# H6 register map
Vendor: Allwinner; Series: H6; File version: 0.1
CPU: CA53 0, little endian, MPU, no FPU, 0 interrupt priority bits
Registers are 32-bit, read-write, reset 0x0 unless marked. A register's access mark holds for its fields unless they carry their own. Offsets are from the block's base; lines under a group give offsets from that group; [hi:lo] are bit positions; {n}, {i} and the like mark numbered series; 'fields as' and 'values as' point back to an identical list; <NAME> marks a mode.

## Memory map
0x00004000 ATE_TV_Encoder
0x00006000 ATE_EPHY
0x01904000 CE_NS
0x01904800 CE_S
0x01905000 EMCE
0x03000000 SYS_CFG
0x03001000 CCU
0x03002000 DMA
0x03003000 MSGBOX
0x03004000 Spinlock
0x03005000 High_Speed_Timer
0x03009000 Timer
0x0300A000 PWM
0x0300B000 PIO
0x030F0000 IOMMU
0x04011000 NDFC0
0x04020000 SMHC0
0x04021000 SMHC1
0x04022000 SMHC2
0x05000000 UART0
0x05000400 UART1
0x05000800 UART2
0x05000C00 UART3
0x05002000 TWI0
0x05002400 TWI1
0x05002800 TWI2
0x05005000 SCR0
0x05005400 SCR1
0x05010000 SPI0
0x05011000 SPI1
0x05020000 EMAC
0x05060000 TSC
0x05060040 TSG
0x05060100 TSF0
0x05060180 TSD0
0x05060200 TSF1
0x05060280 TSD1
0x05060300 TSF2
0x05060380 TSD2
0x05060400 TSF3
0x05060480 TSD3
0x05060500 TSF4
0x05060580 TSD4
0x05070400 CIR_TX
0x05070400 Thermal_Sensor
0x0508F000 I2S/PCM3(used_for_Audio_Codec)
0x05090000 I2S/PCM0
0x05091000 I2S/PCM1(used_for_HDMI)
0x05092000 I2S/PCM2
0x05093000 OWA
0x05095000 DMIC
0x05097000 AHUB
0x05311000 USB2.0_HOST
0x06511000 TCON_LCD0
0x06515000 TCON_TV0
0x06620000 CSI_BASE
0x06620000 CSI_TOP
0x06621000 CSI_PARSER
0x06623000 CSI_DMA0
0x06623100 CSI_DMA1
0x0662E000 CSI_CCI0
0x07000000 RTC
0x07022000 PIO
0x07040000 CIR_RX
0x07040400 R_OWC
0x07080000 R_UART0
0x07081400 R-TWI
0x08100000 CPU_SUBSYS_CTRL
0x09010000 CPU_CFG

## SYS_CFG
Base 0x03000000
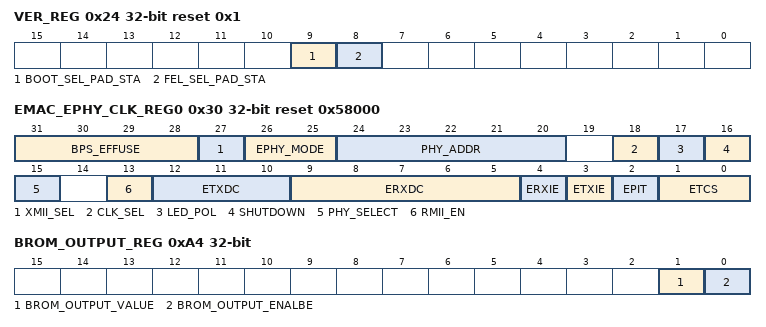
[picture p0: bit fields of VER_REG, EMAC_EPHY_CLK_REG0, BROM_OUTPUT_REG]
0x24 VER_REG reset 0x1 (reset mask 0xFFFF8007) — Version Register
  [9] BOOT_SEL_PAD_STA ro — 0:SMHC0->SMHC2->NAND FLASH->SPI_NOR 1:SMHC0->NAND FLASH->SMHC2->SPI_NOR
  [8] FEL_SEL_PAD_STA ro — Fel_Select_Pin_Status 0: Run_FEL 1:Try Media Boot
    0=Run_FEL; 1=Try (Try Media Boot)
0x30 EMAC_EPHY_CLK_REG0 reset 0x58000 — EMAC-EPHY Clock Register 0
  [31:28] BPS_EFFUSE
  [27] XMII_SEL — 0: Internal SMI and MII 1: External SMI and MII
    0=Internal SMI and MII; 1=External SMI and MII
  [26:25] EPHY_MODE — Operation Mode Selection 00 : Normal Mode 01 : Sim Mode 10 : AFE Test Mode 11 : /
  [24:20] PHY_ADDR — PHY Address
  [18] CLK_SEL — 0 : 25MHz 1 : 24MHz
  [17] LED_POL — 0 : High active 1 : Low active
  [16] SHUTDOWN — 0 : Power up 1 : Shutdown
  [15] PHY_SELECT — 0 : External PHY 1 : Internal PHY
  [13] RMII_EN — 0 : Disable RMII Module 1 : Enable RMII Module When this bit assert, MII or RGMII interface is disabled( This means bit13 is prior to bit2)
  [12:10] ETXDC — Configure EMAC Transmit Clock Delay Chain.
  [9:5] ERXDC — Configure EMAC Receive Clock Delay Chain.
  [4] ERXIE — Enable EMAC Receive Clock Invertor. 0: Disable 1: Enable
    0=Disable; 1=Enable
  [3] ETXIE — Enable EMAC Transmit Clock Invertor. 0: Disable 1: Enable
    0=Disable; 1=Enable
  [2] EPIT — EMAC PHY Interface Type 0: MII 1: RGMII
    0=MII; 1=RGMII
  [1:0] ETCS — EMAC Transmit Clock Source 00: Transmit clock source for MII 01: External transmit clock source for RMII and RGMII 10: Internal transmit clock source for RMII and RGMII 11: Reserved
    0=Transmit clock source for MII; 1=External transmit clock source for RMII and RGMII; 2=Internal transmit clock source for RMII and RGMII
0xA4 BROM_OUTPUT_REG — BROM Output Register
  [1] BROM_OUTPUT_VALUE — 0: U-Boot pin output 0 1: U-Boot pin output 1
    0=U_minus_Boot_pin_output_0 (U-Boot pin output 0); 1=U_minus_Boot_pin_output_1 (U-Boot pin output 1)
  [0] BROM_OUTPUT_ENALBE — 0: Disable U-Boot pin output 1: Enable U-Boot pin output
    0=Disable U-Boot pin output; 1=Enable U-Boot pin output

## CPU_SUBSYS_CTRL
Base 0x08100000
0x00 GENER_CTRL_REG0 — General Control Register0
  [0] GIC_CFGSDISABLE — Disables write access to some secure GIC registers.
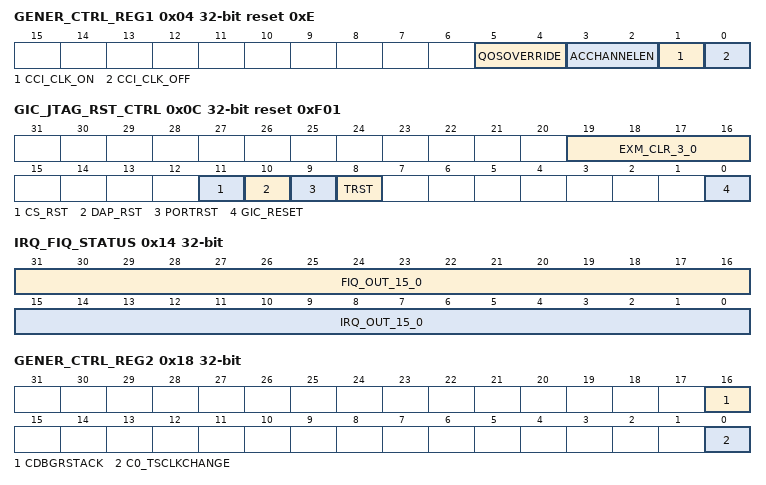
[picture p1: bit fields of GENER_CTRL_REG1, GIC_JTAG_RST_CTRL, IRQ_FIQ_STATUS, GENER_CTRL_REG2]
0x04 GENER_CTRL_REG1 reset 0xE — General Control Register1
  [5:4] QOSOVERRIDE — If HIGH, internally generated values override the ARQOS and AWQOS inputs. One bit exists for each slave interface.
  [3:2] ACCHANNELEN — If LOW, then AC requests are not issued on the corresponding slave interface. One bit exists for each slave interface.
  [1] CCI_CLK_ON — Set 1 means CCI Clock always on.
  [0] CCI_CLK_OFF — Set 1 means CCI Clock always off. NOTE When CCI_CLK_OFF and CCI_CLK_ON are valid at the same time ,CCI_CLK_OFF has the higher priority than CCI_CLK_ON.
0x0C GIC_JTAG_RST_CTRL reset 0xF01 — GIC and Jtag Reset Control Register
  [19:16] EXM_CLR_3_0 — EXM_CLR[3:0] Clear the status of interface, for debug
  [11] CS_RST — CoreSight Reset. 0: assert 1: de-assert.
    0=assert; 1=deassert
  [10] DAP_RST — DAP Reset. 0: assert 1: de-assert.
    0=assert; 1=deassert
  [9] PORTRST — Jtag portrst. 0: assert 1: de-assert.
    0=assert; 1=deassert
  [8] TRST — Jtag trst. 0: assert 1: de-assert.
    0=assert; 1=deassert
  [0] GIC_RESET — Gic_reset_cpu_reg 0: assert 1: de-assert.
    0=assert; 1=deassert
0x10 C0_INT_EN reset 0xFFFF — Cluster0 Interrupt Enable Control Register
  [15:0] C0_GIC_EN — Interrupt enable control register. Mask irq_out/firq_out to system domain.
0x14 IRQ_FIQ_STATUS — GIC IRQ/FIQ Status Register
  [31:16] FIQ_OUT_15_0, [15:0] IRQ_OUT_15_0
0x18 GENER_CTRL_REG2 — General Control Register2
  [16] CDBGRSTACK, [0] C0_TSCLKCHANGE

## Licence text in the file
questionable
